# PIC32CK1012SG01064 register map
Vendor: Microchip Technology; Series: PIC32CKSG01; File version: 0
CPU: CM33 r0p0, little endian, MPU, FPU, DSP, 3 interrupt priority bits, 159 interrupts, 18 SAU regions
Registers are 32-bit, read-write, reset 0x0 unless marked. A register's access mark holds for its fields unless they carry their own. Offsets are from the block's base; [hi:lo] are bit positions; lines under a group give offsets from that group; {n}, {i} and the like mark numbered series; 'fields as' and 'values as' point back to an identical list.

## PCC — Parallel Capture Controller
Base 0x45018000
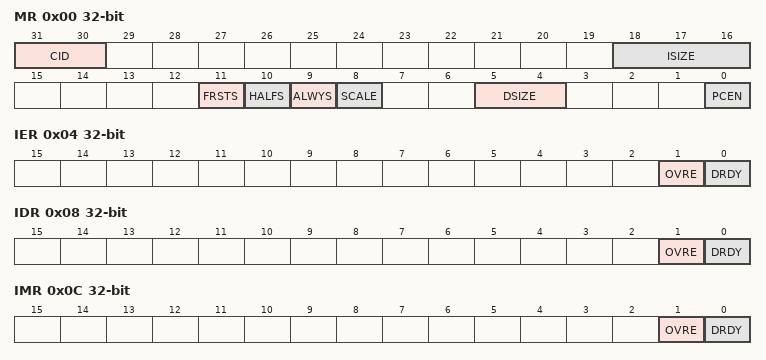
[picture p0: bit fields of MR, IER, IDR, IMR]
0x00 MR — Mode Register
  [31:30] CID — Clear If Disabled
  [18:16] ISIZE — Input Data Size
  [11] FRSTS — First sample
  [10] HALFS — Half Sampling
  [9] ALWYS — Always Sampling
  [8] SCALE — Scale data
  [5:4] DSIZE — Data size
  [0] PCEN — Parallel Capture Enable
0x04 IER wo — Interrupt Enable Register
  [1] OVRE — Overrun Error Interrupt Enable
  [0] DRDY — Data Ready Interrupt Enable
0x08 IDR wo — Interrupt Disable Register
  [1] OVRE — Overrun Error Interrupt Disable
  [0] DRDY — Data Ready Interrupt Disable
0x0C IMR ro — Interrupt Mask Register
  [1] OVRE — Overrun Error Interrupt Mask
  [0] DRDY — Data Ready Interrupt Mask
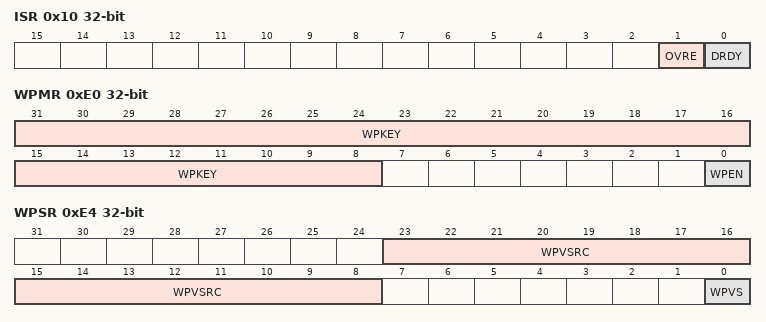
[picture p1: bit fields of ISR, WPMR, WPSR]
0x10 ISR ro — Interrupt Status Register
  [1] OVRE — Overrun Error Interrupt Status
  [0] DRDY — Data Ready Interrupt Status
0x14 RHR ro — Reception Holding Register
  [31:0] RDATA — Reception Data
0xE0 WPMR — Write Protection Mode Register
  [31:8] WPKEY — Write Protection Key
  [0] WPEN — Write Protection Enable
0xE4 WPSR ro — Write Protection Status Register
  [23:8] WPVSRC — Write Protection Violation Status
  [0] WPVS — Write Protection Violation Source

## PM — Power Manager
Base 0x44006000
0x00 CTRLA 8-bit — Control A
  [2] IORET — I/O Retention
    0=NOIORET (When the device exits the HIBERNATE or BACKUP mode, the I/O line configuration are released.); 1=IORET (When the device exits the HIBERNATE or BACKUP mode, the I/O line configuration are stretched.)
0x01 SLEEPCFG 8-bit reset 0x2 — Sleep Configuration
  [2:0] SLEEPMODE
    2=IDLE (CPU, AHB and APB clocks are OFF); 4=STANDBY (All Clocks are OFF); 5=HIBERNATE (Backup domain is ON as well as some PDRAMs); 6=BACKUP (Only Backup domain is powered ON); 7=OFF (All power domains are powered OFF)
0x04 INTENCLR 8-bit write-1-clears — Interrupt Enable Clear
  [0] SLEEPRDY — Backup Sleep Mode Entry Ready Enable
0x05 INTENSET 8-bit write-1-sets — Interrupt Enable Set
  [0] SLEEPRDY — Backup Sleep Mode Entry Ready Enable
0x06 INTFLAG 8-bit reset 0x1 write-1-clears — Interrupt Flag Status and Clear
  [0] SLEEPRDY — Backup Sleep Mode Entry Ready
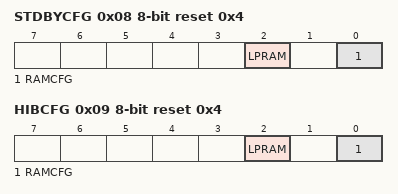
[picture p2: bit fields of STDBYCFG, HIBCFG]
0x08 STDBYCFG 8-bit reset 0x4 — Standby Configuration
  [2] LPRAM — Low Power RAM Enable
  [0] RAMCFG — Ram Configuration
    0=RET (All the RAMs are retained); 1=OFF (Only the first 32K bytes are retained)
0x09 HIBCFG 8-bit reset 0x4 — Hibernate Configuration
  fields as STDBYCFG

## PORT — Port Module
Base 0x44800000
Same registers: PORT_SEC 0x44801000
{0x0+0x80*i} GROUP[{i}] (i=0..3) group
  0x00 DIR — Data Direction
    [31:0] DIR — Port Data Direction
  0x04 DIRCLR — Data Direction Clear
    [31:0] DIRCLR — Port Data Direction Clear
  0x08 DIRSET — Data Direction Set
    [31:0] DIRSET — Port Data Direction Set
  0x0C DIRTGL — Data Direction Toggle
    [31:0] DIRTGL — Port Data Direction Toggle
  0x10 OUT — Data Output Value
    [31:0] OUT — PORT Data Output Value
  0x14 OUTCLR — Data Output Value Clear
    [31:0] OUTCLR — PORT Data Output Value Clear
  0x18 OUTSET — Data Output Value Set
    [31:0] OUTSET — PORT Data Output Value Set
  0x1C OUTTGL — Data Output Value Toggle
    [31:0] OUTTGL — PORT Data Output Value Toggle
  0x20 IN ro — Data Input Value
    [31:0] IN — PORT Data Input Value
  0x24 CTRL — Control
    [31:0] SAMPLING — Input Sampling Mode
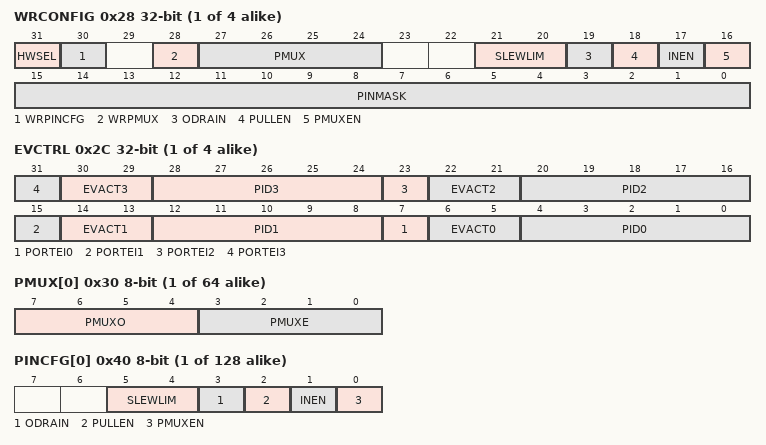
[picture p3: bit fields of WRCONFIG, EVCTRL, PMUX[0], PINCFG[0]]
  0x28 WRCONFIG wo — Write Configuration
    [31] HWSEL — Half-Word Select
    [30] WRPINCFG — Write PINCFG
    [28] WRPMUX — Write PMUX
    [27:24] PMUX — Peripheral Multiplexing
    [21:20] SLEWLIM — Output Driver Slew Rate Selection
    [19] ODRAIN — Open Drain Output
    [18] PULLEN — Pull Enable
    [17] INEN — Input Enable
    [16] PMUXEN — Peripheral Multiplexer Enable
    [15:0] PINMASK — Pin Mask for Multiple Pin Configuration
  0x2C EVCTRL — Event Input Control
    [8n+7] PORTEI{n} (n=0..3) — PORT Event Input Enable {n}
    [30:29] EVACT3 — PORT Event Action 3
    [8n+4:8n] PID{n} (n=0..3) — PORT Event Pin Identifier {n}
    [22:21] EVACT2 — PORT Event Action 2
    [14:13] EVACT1 — PORT Event Action 1
    [6:5] EVACT0 — PORT Event Action 0
      0=OUT (Event output to pin); 1=SET (Set output register of pin on event); 2=CLR (Clear output register of pin on event); 3=TGL (Toggle output register of pin on event)
  {0x30+j} PMUX[{j}] (j=0..15) 8-bit — Peripheral Multiplexing
    [7:4] PMUXO — Peripheral Multiplexing for Odd-Numbered Pin
      0=A (External Interrupts); 1=B (ADC and Analog Comparator); 2=C (SERCOMn (UART, I2C, SPI)); 3=D (SERCOMn Alt (UART, I2C, SPI)); 4=E (External Bus Interface); 5=F (Timer/Counter controller); 6=G (Timer/Counter controller and Positional Decoder Alt); 7=H (SQI/CAN/USB/CM33 Trace); 8=I (SD/MMC Host Controller (Memory Card Interface)); 9=J (SPI_IXS Audio); 10=K (Parallel Capture Controller); 11=L (Ethernet); 12=M (GCLK/CCL/AC Alt); 13=P (Peripheral Touch Controller and JTAG/SWD Debug Interfaces)
    [3:0] PMUXE — Peripheral Multiplexing for Even-Numbered Pin
      values as PMUXO
  {0x40+j} PINCFG[{j}] (j=0..31) 8-bit — Pin Configuration
    [5:4] SLEWLIM — Output Driver Slew Rate Selection
      0=FAST (Slew rate control disabled (fast rise/fall time operation)); 1=SLOW4 (Slew rate control enabled (4x slower)); 2=SLOW8 (Slew rate control enabled (8x slower)); 3=SLOW12 (Slew rate control enabled (12x slower))
    [3] ODRAIN — Open Drain Output
    [2] PULLEN — Pull Enable
    [1] INEN — Input Enable
    [0] PMUXEN — Peripheral Multiplexer Enable
  0x60 INTENCLR write-1-clears — Interrupt Enable Clear
    [0] NSCHK — Non-Secure Check Interrupt Enable
  0x64 INTENSET write-1-sets — Interrupt Enable Set
    [0] NSCHK — Non-Secure Check Interrupt Enable
  0x68 INTFLAG write-1-clears — Interrupt Flag Status and Clear
    [0] NSCHK — Non-Secure Check
  0x6C NONSEC — Security Attribution
    [31:0] NONSEC — Port Security Attribution
  0x70 NSCHK — Security Attribution Check
    [31:0] NSCHK — Port Security Attribution Check

## Notices in the file
Copyright (c) 2026 Microchip Technology Inc.
SPDX-License-Identifier: Apache-2.0
Licensed under the Apache License, Version 2.0 (the "License");
you may not use this file except in compliance with the License.
You may obtain a copy of the License at
http://www.apache.org/licenses/LICENSE-2.0
Unless required by applicable law or agreed to in writing, software
distributed under the License is distributed on an "AS IS" BASIS,
WITHOUT WARRANTIES OR CONDITIONS OF ANY KIND, either express or implied.
See the License for the specific language governing permissions and
limitations under the License.
